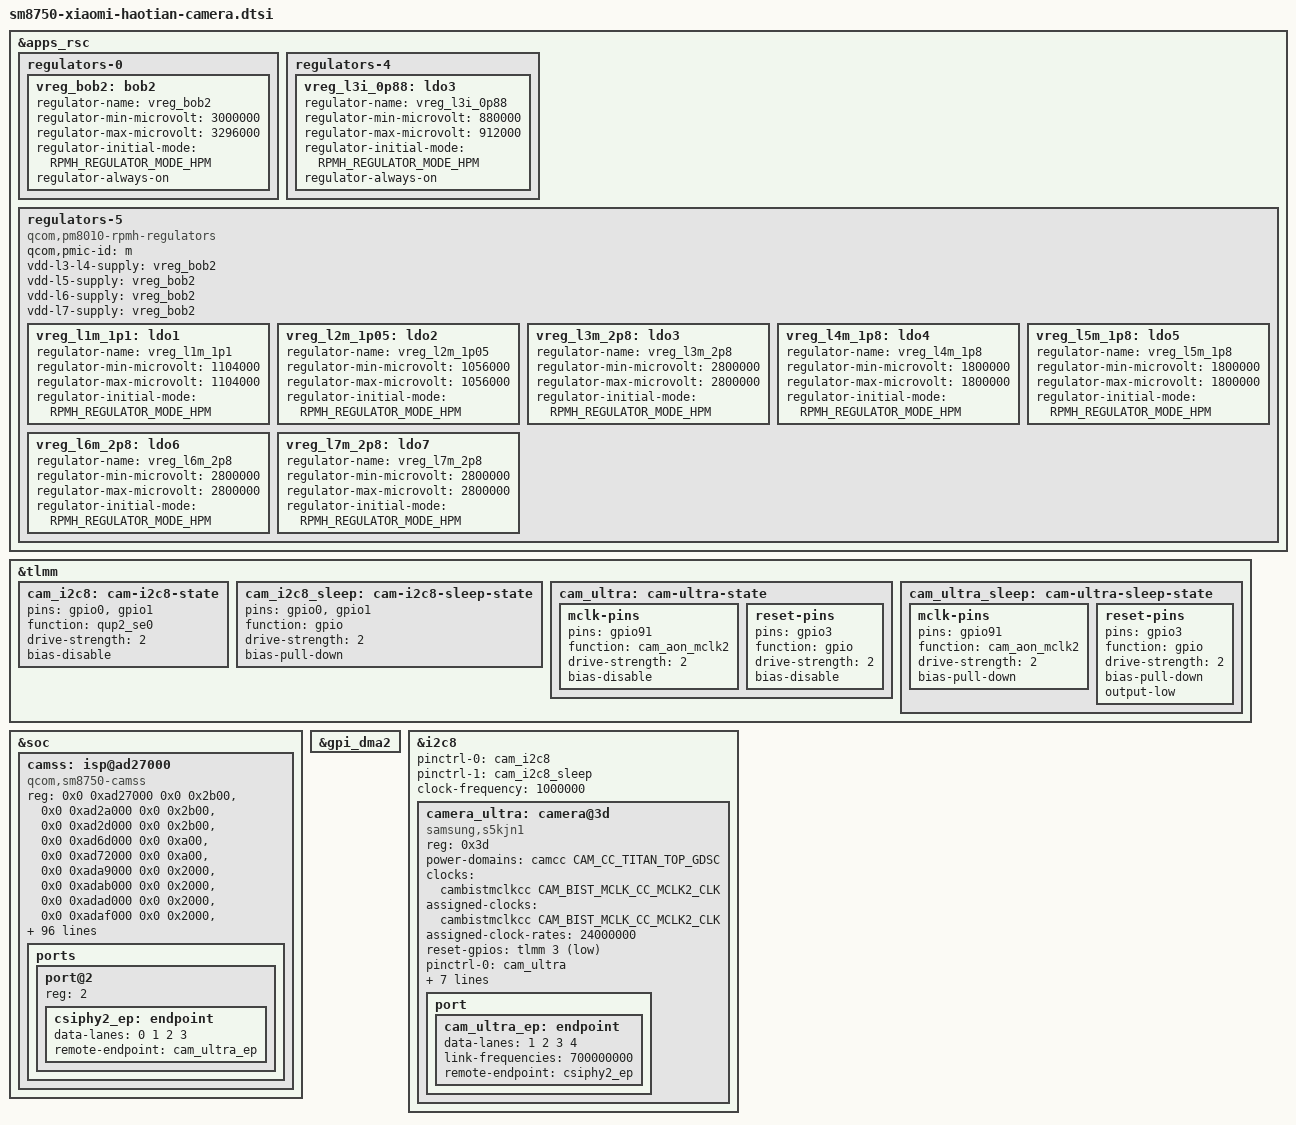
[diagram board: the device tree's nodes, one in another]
// SPDX-License-Identifier: GPL-2.0-only
/*
 * Xiaomi 15 Pro (haotian) mainline camera nodes.
 *
 * Ultrawide rear camera (Samsung S5KJN1) on i2c8 (QUPv3 SE8, addr 0x3d)
 * routed to CSIPHY2 via qcom,sm8750-camss, powered by PM8010M (L2M/L4M/L6M/L7M)
 * and PM8550 BOB2.
 */
#include <dt-bindings/clock/qcom,sm8750-cambistmclkcc.h>
#include <dt-bindings/clock/qcom,sm8750-camcc.h>

&apps_rsc {
	regulators-0 {
		vreg_bob2: bob2 {
			regulator-name = "vreg_bob2";
			regulator-min-microvolt = <3000000>;
			regulator-max-microvolt = <3296000>;
			regulator-initial-mode = <RPMH_REGULATOR_MODE_HPM>;
			regulator-always-on;
		};
	};

	regulators-4 {
		/*
		 * Shared by UFS PHY vdda-qref, DSI PHY vdda-0p9, and CSI PHYs.
		 * Keep always-on so camera power-down never drops UFS QREF.
		 */
		vreg_l3i_0p88: ldo3 {
			regulator-name = "vreg_l3i_0p88";
			regulator-min-microvolt = <880000>;
			regulator-max-microvolt = <912000>;
			regulator-initial-mode = <RPMH_REGULATOR_MODE_HPM>;
			regulator-always-on;
		};
	};

	regulators-5 {
		compatible = "qcom,pm8010-rpmh-regulators";
		qcom,pmic-id = "m";

		vdd-l3-l4-supply = <&vreg_bob2>;
		vdd-l5-supply = <&vreg_bob2>;
		vdd-l6-supply = <&vreg_bob2>;
		vdd-l7-supply = <&vreg_bob2>;

		vreg_l1m_1p1: ldo1 {
			regulator-name = "vreg_l1m_1p1";
			regulator-min-microvolt = <1104000>;
			regulator-max-microvolt = <1104000>;
			regulator-initial-mode = <RPMH_REGULATOR_MODE_HPM>;
		};

		vreg_l2m_1p05: ldo2 {
			regulator-name = "vreg_l2m_1p05";
			regulator-min-microvolt = <1056000>;
			regulator-max-microvolt = <1056000>;
			regulator-initial-mode = <RPMH_REGULATOR_MODE_HPM>;
		};

		vreg_l3m_2p8: ldo3 {
			regulator-name = "vreg_l3m_2p8";
			regulator-min-microvolt = <2800000>;
			regulator-max-microvolt = <2800000>;
			regulator-initial-mode = <RPMH_REGULATOR_MODE_HPM>;
		};

		vreg_l4m_1p8: ldo4 {
			regulator-name = "vreg_l4m_1p8";
			regulator-min-microvolt = <1800000>;
			regulator-max-microvolt = <1800000>;
			regulator-initial-mode = <RPMH_REGULATOR_MODE_HPM>;
		};

		vreg_l5m_1p8: ldo5 {
			regulator-name = "vreg_l5m_1p8";
			regulator-min-microvolt = <1800000>;
			regulator-max-microvolt = <1800000>;
			regulator-initial-mode = <RPMH_REGULATOR_MODE_HPM>;
		};

		vreg_l6m_2p8: ldo6 {
			regulator-name = "vreg_l6m_2p8";
			regulator-min-microvolt = <2800000>;
			regulator-max-microvolt = <2800000>;
			regulator-initial-mode = <RPMH_REGULATOR_MODE_HPM>;
		};

		vreg_l7m_2p8: ldo7 {
			regulator-name = "vreg_l7m_2p8";
			regulator-min-microvolt = <2800000>;
			regulator-max-microvolt = <2800000>;
			regulator-initial-mode = <RPMH_REGULATOR_MODE_HPM>;
		};
	};
};

&tlmm {
	cam_i2c8: cam-i2c8-state {
		pins = "gpio0", "gpio1";
		function = "qup2_se0";
		drive-strength = <2>;
		bias-disable;
	};

	cam_i2c8_sleep: cam-i2c8-sleep-state {
		pins = "gpio0", "gpio1";
		function = "gpio";
		drive-strength = <2>;
		bias-pull-down;
	};

	cam_ultra: cam-ultra-state {
		mclk-pins {
			pins = "gpio91";
			function = "cam_aon_mclk2";
			drive-strength = <2>;
			bias-disable;
		};

		reset-pins {
			pins = "gpio3";
			function = "gpio";
			drive-strength = <2>;
			bias-disable;
		};
	};

	cam_ultra_sleep: cam-ultra-sleep-state {
		mclk-pins {
			pins = "gpio91";
			function = "cam_aon_mclk2";
			drive-strength = <2>;
			bias-pull-down;
		};

		reset-pins {
			pins = "gpio3";
			function = "gpio";
			drive-strength = <2>;
			bias-pull-down;
			output-low;
		};
	};
};

&soc {
	camss: isp@ad27000 {
		compatible = "qcom,sm8750-camss";
		reg = <0x0 0xad27000 0x0 0x2b00>,
		      <0x0 0xad2a000 0x0 0x2b00>,
		      <0x0 0xad2d000 0x0 0x2b00>,
		      <0x0 0xad6d000 0x0 0xa00>,
		      <0x0 0xad72000 0x0 0xa00>,
		      <0x0 0xada9000 0x0 0x2000>,
		      <0x0 0xadab000 0x0 0x2000>,
		      <0x0 0xadad000 0x0 0x2000>,
		      <0x0 0xadaf000 0x0 0x2000>,
		      <0x0 0xadb1000 0x0 0x2000>,
		      <0x0 0xadb3000 0x0 0x2000>,
		      <0x0 0xad8b000 0x0 0x400>,
		      <0x0 0xad8c000 0x0 0x400>,
		      <0x0 0xad8d000 0x0 0x400>,
		      <0x0 0xac86000 0x0 0x10000>,
		      <0x0 0xac96000 0x0 0x10000>,
		      <0x0 0xaca6000 0x0 0x10000>,
		      <0x0 0xad6e000 0x0 0x3000>,
		      <0x0 0xad73000 0x0 0x3000>;
		reg-names = "csid0",
			    "csid1",
			    "csid2",
			    "csid_lite0",
			    "csid_lite1",
			    "csiphy0",
			    "csiphy1",
			    "csiphy2",
			    "csiphy3",
			    "csiphy4",
			    "csiphy5",
			    "csitpg0",
			    "csitpg1",
			    "csitpg2",
			    "vfe0",
			    "vfe1",
			    "vfe2",
			    "vfe_lite0",
			    "vfe_lite1";

		clocks = <&camcc CAM_CC_CAMNOC_NRT_AXI_CLK>,
			 <&camcc CAM_CC_CAMNOC_RT_AXI_CLK>,
			 <&camcc CAM_CC_CAM_TOP_AHB_CLK>,
			 <&camcc CAM_CC_CAM_TOP_FAST_AHB_CLK>,
			 <&camcc CAM_CC_CAMNOC_RT_TFE_0_MAIN_CLK>,
			 <&camcc CAM_CC_CAMNOC_RT_TFE_1_MAIN_CLK>,
			 <&camcc CAM_CC_CAMNOC_RT_TFE_2_MAIN_CLK>,
			 <&camcc CAM_CC_CAMNOC_RT_IFE_LITE_CLK>,
			 <&camcc CAM_CC_CAMNOC_RT_TFE_0_BAYER_CLK>,
			 <&camcc CAM_CC_CAMNOC_RT_TFE_1_BAYER_CLK>,
			 <&camcc CAM_CC_CAMNOC_RT_TFE_2_BAYER_CLK>,
			 <&camcc CAM_CC_CSID_CLK>,
			 <&camcc CAM_CC_CSID_CSIPHY_RX_CLK>,
			 <&camcc CAM_CC_CSIPHY0_CLK>,
			 <&camcc CAM_CC_CSI0PHYTIMER_CLK>,
			 <&camcc CAM_CC_CSIPHY1_CLK>,
			 <&camcc CAM_CC_CSI1PHYTIMER_CLK>,
			 <&camcc CAM_CC_CSIPHY2_CLK>,
			 <&camcc CAM_CC_CSI2PHYTIMER_CLK>,
			 <&camcc CAM_CC_CSIPHY3_CLK>,
			 <&camcc CAM_CC_CSI3PHYTIMER_CLK>,
			 <&camcc CAM_CC_CSIPHY4_CLK>,
			 <&camcc CAM_CC_CSI4PHYTIMER_CLK>,
			 <&camcc CAM_CC_CSIPHY5_CLK>,
			 <&camcc CAM_CC_CSI5PHYTIMER_CLK>,
			 <&gcc GCC_CAMERA_HF_AXI_CLK>,
			 <&gcc GCC_CAMERA_SF_AXI_CLK>,
			 <&camcc CAM_CC_TFE_0_MAIN_CLK>,
			 <&camcc CAM_CC_TFE_0_MAIN_FAST_AHB_CLK>,
			 <&camcc CAM_CC_TFE_1_MAIN_CLK>,
			 <&camcc CAM_CC_TFE_1_MAIN_FAST_AHB_CLK>,
			 <&camcc CAM_CC_TFE_2_MAIN_CLK>,
			 <&camcc CAM_CC_TFE_2_MAIN_FAST_AHB_CLK>,
			 <&camcc CAM_CC_TFE_0_BAYER_CLK>,
			 <&camcc CAM_CC_TFE_0_BAYER_FAST_AHB_CLK>,
			 <&camcc CAM_CC_TFE_1_BAYER_CLK>,
			 <&camcc CAM_CC_TFE_1_BAYER_FAST_AHB_CLK>,
			 <&camcc CAM_CC_TFE_2_BAYER_CLK>,
			 <&camcc CAM_CC_TFE_2_BAYER_FAST_AHB_CLK>,
			 <&camcc CAM_CC_IFE_LITE_CLK>,
			 <&camcc CAM_CC_IFE_LITE_AHB_CLK>,
			 <&camcc CAM_CC_IFE_LITE_CPHY_RX_CLK>,
			 <&camcc CAM_CC_IFE_LITE_CSID_CLK>,
			 <&camcc CAM_CC_QDSS_DEBUG_XO_CLK>;
		clock-names = "camnoc_nrt_axi",
			      "camnoc_rt_axi",
			      "cpas_ahb",
			      "cpas_fast_ahb",
			      "cpas_vfe0",
			      "cpas_vfe1",
			      "cpas_vfe2",
			      "cpas_vfe_lite",
			      "cpas_vfe0_bayer",
			      "cpas_vfe1_bayer",
			      "cpas_vfe2_bayer",
			      "csid",
			      "csid_csiphy_rx",
			      "csiphy0",
			      "csiphy0_timer",
			      "csiphy1",
			      "csiphy1_timer",
			      "csiphy2",
			      "csiphy2_timer",
			      "csiphy3",
			      "csiphy3_timer",
			      "csiphy4",
			      "csiphy4_timer",
			      "csiphy5",
			      "csiphy5_timer",
			      "gcc_axi_hf",
			      "gcc_axi_sf",
			      "vfe0",
			      "vfe0_fast_ahb",
			      "vfe1",
			      "vfe1_fast_ahb",
			      "vfe2",
			      "vfe2_fast_ahb",
			      "vfe0_bayer",
			      "vfe0_bayer_fast_ahb",
			      "vfe1_bayer",
			      "vfe1_bayer_fast_ahb",
			      "vfe2_bayer",
			      "vfe2_bayer_fast_ahb",
			      "vfe_lite",
			      "vfe_lite_ahb",
			      "vfe_lite_cphy_rx",
			      "vfe_lite_csid",
			      "qdss_debug_xo";

		interrupts = <GIC_SPI 601 IRQ_TYPE_EDGE_RISING>,
			     <GIC_SPI 603 IRQ_TYPE_EDGE_RISING>,
			     <GIC_SPI 431 IRQ_TYPE_EDGE_RISING>,
			     <GIC_SPI 605 IRQ_TYPE_EDGE_RISING>,
			     <GIC_SPI 376 IRQ_TYPE_EDGE_RISING>,
			     <GIC_SPI 477 IRQ_TYPE_EDGE_RISING>,
			     <GIC_SPI 478 IRQ_TYPE_EDGE_RISING>,
			     <GIC_SPI 479 IRQ_TYPE_EDGE_RISING>,
			     <GIC_SPI 448 IRQ_TYPE_EDGE_RISING>,
			     <GIC_SPI 122 IRQ_TYPE_EDGE_RISING>,
			     <GIC_SPI 89 IRQ_TYPE_EDGE_RISING>,
			     <GIC_SPI 433 IRQ_TYPE_EDGE_RISING>,
			     <GIC_SPI 436 IRQ_TYPE_EDGE_RISING>,
			     <GIC_SPI 457 IRQ_TYPE_EDGE_RISING>,
			     <GIC_SPI 606 IRQ_TYPE_EDGE_RISING>,
			     <GIC_SPI 377 IRQ_TYPE_EDGE_RISING>;
		interrupt-names = "csid0",
				  "csid1",
				  "csid2",
				  "csid_lite0",
				  "csid_lite1",
				  "csiphy0",
				  "csiphy1",
				  "csiphy2",
				  "csiphy3",
				  "csiphy4",
				  "csiphy5",
				  "vfe0",
				  "vfe1",
				  "vfe2",
				  "vfe_lite0",
				  "vfe_lite1";

		interconnects = <&gem_noc MASTER_APPSS_PROC QCOM_ICC_TAG_ACTIVE_ONLY
				 &config_noc SLAVE_CAMERA_CFG QCOM_ICC_TAG_ACTIVE_ONLY>,
				<&mmss_noc MASTER_CAMNOC_HF QCOM_ICC_TAG_ALWAYS
				 &mc_virt SLAVE_EBI1 QCOM_ICC_TAG_ALWAYS>,
				<&mmss_noc MASTER_CAMNOC_SF QCOM_ICC_TAG_ALWAYS
				 &mc_virt SLAVE_EBI1 QCOM_ICC_TAG_ALWAYS>,
				<&mmss_noc MASTER_CAMNOC_NRT_ICP_SF QCOM_ICC_TAG_ALWAYS
				 &mc_virt SLAVE_EBI1 QCOM_ICC_TAG_ALWAYS>;
		interconnect-names = "ahb",
				     "hf_mnoc",
				     "sf_mnoc",
				     "sf_icp_mnoc";

		iommus = <&apps_smmu 0x1c00 0x0>;

		power-domains = <&camcc CAM_CC_TFE_0_GDSC>,
				<&camcc CAM_CC_TFE_1_GDSC>,
				<&camcc CAM_CC_TFE_2_GDSC>,
				<&camcc CAM_CC_TITAN_TOP_GDSC>;
		power-domain-names = "ife0",
				     "ife1",
				     "ife2",
				     "top";

		vdd-csiphy0-0p9-supply = <&vreg_l1f_0p88>;
		vdd-csiphy0-1p2-supply = <&vreg_l3g_1p2>;
		vdd-csiphy1-0p9-supply = <&vreg_l1f_0p88>;
		vdd-csiphy1-1p2-supply = <&vreg_l3g_1p2>;
		vdd-csiphy2-0p9-supply = <&vreg_l3i_0p88>;
		vdd-csiphy2-1p2-supply = <&vreg_l3g_1p2>;
		vdd-csiphy3-0p9-supply = <&vreg_l1f_0p88>;
		vdd-csiphy3-1p2-supply = <&vreg_l3g_1p2>;
		vdd-csiphy4-0p9-supply = <&vreg_l3i_0p88>;
		vdd-csiphy4-1p2-supply = <&vreg_l3g_1p2>;
		vdd-csiphy5-0p9-supply = <&vreg_l1f_0p88>;
		vdd-csiphy5-1p2-supply = <&vreg_l3g_1p2>;

		ports {
			#address-cells = <1>;
			#size-cells = <0>;

			port@2 {
				reg = <2>;

				csiphy2_ep: endpoint {
					data-lanes = <0 1 2 3>;
					remote-endpoint = <&cam_ultra_ep>;
				};
			};
		};
	};
};

&gpi_dma2 {
	status = "okay";
};

&i2c8 {
	status = "okay";
	pinctrl-names = "default", "sleep";
	pinctrl-0 = <&cam_i2c8>;
	pinctrl-1 = <&cam_i2c8_sleep>;
	clock-frequency = <1000000>;

	camera_ultra: camera@3d {
		compatible = "samsung,s5kjn1";
		reg = <0x3d>;
		power-domains = <&camcc CAM_CC_TITAN_TOP_GDSC>;
		clocks = <&cambistmclkcc CAM_BIST_MCLK_CC_MCLK2_CLK>;
		assigned-clocks = <&cambistmclkcc CAM_BIST_MCLK_CC_MCLK2_CLK>;
		assigned-clock-rates = <24000000>;
		reset-gpios = <&tlmm 3 GPIO_ACTIVE_LOW>;
		pinctrl-names = "default", "sleep";
		pinctrl-0 = <&cam_ultra>;
		pinctrl-1 = <&cam_ultra_sleep>;
		afvdd-supply = <&vreg_l7m_2p8>;
		vdda-supply = <&vreg_l6m_2p8>;
		vddd-supply = <&vreg_l2m_1p05>;
		vddio-supply = <&vreg_l4m_1p8>;
		orientation = <1>;
		rotation = <270>;

		port {
			cam_ultra_ep: endpoint {
				data-lanes = <1 2 3 4>;
				link-frequencies = /bits/ 64 <700000000>;
				remote-endpoint = <&csiphy2_ep>;
			};
		};
	};
};
